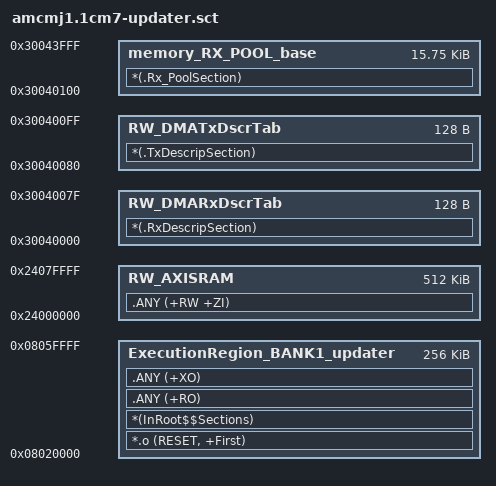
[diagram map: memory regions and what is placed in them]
; amcmj1-updater running on cm7. it uses following FLASH and RAM resources:
; 
; - FLASH: 1st bank @ 0x08020000 for a size of 256k
; 
; - RAM: AXI SRAM @ 0x24000000 for a size of 512k
; 
; the memory for IPC is @ 0x1003FFC0, on the top 64 bytes of SRAM1-SRAM2 used by the CM4

LoadRegion_BANK1_updater 0x08020000 0x00040000  {  
  
  ; execution region is in flash
  ExecutionRegion_BANK1_updater 0x08020000 0x00040000  {  
   *.o (RESET, +First)
   *(InRoot$$Sections)
   .ANY (+RO)
   .ANY (+XO)
  }

;  ; ram for lwip heap - SRAM1 @ 0x30004000
;  ; 0x3800 = 14*1024 = the lwip.MEM_SIZE, 0x30004000 = LWIP_RAM_HEAP_POINTER
;  RW_LWIP_HEAP 0x30004000 EMPTY 0x3800  {
;  }  

  ; w/ 0x80 = 128 i can have up to 5 ETH_DMADescTypeDef, so check that ETH_TX_DESC_CNT and ETH_RX_DESC_CNT are <=5. 
  RW_DMARxDscrTab 0x30040000 0x80 {
  *(.RxDescripSection)
  }
  RW_DMATxDscrTab 0x30040080 0x80 {
  *(.TxDescripSection)
  }
  
  ; w/ 0x3F00 (16128 byte) i can accomodate ETH_RX_BUFFER_CNT * sizeof(RxBuff_t) = 8 в 1572 = 12576 byte (0x3120)
  memory_RX_POOL_base 0x30040100 0x3F00 {
  *(.Rx_PoolSection)
  }
  
  ; ram: AXI SRAM @ 0x24000000
  RW_AXISRAM 0x24000000 0x00080000  {
   .ANY (+RW +ZI)
  }

  
}

